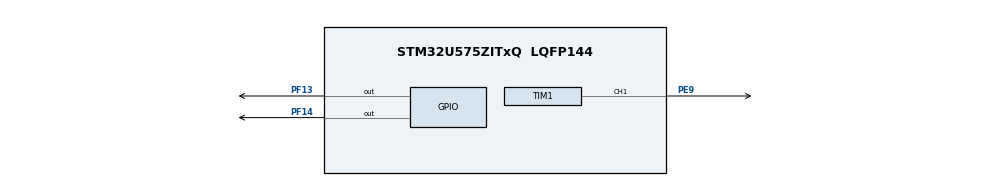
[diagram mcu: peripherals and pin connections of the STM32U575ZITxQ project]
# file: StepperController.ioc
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CORTEX_M33_NS.userName=CORTEX_M33
Mcu.Family=STM32U5
Mcu.Name=STM32U575ZITxQ
Mcu.Package=LQFP144
NUCLEO-U575ZI-Q.BUTTON=1
NUCLEO-U575ZI-Q.Bsp_Common_DEMO=true
NUCLEO-U575ZI-Q.LD1=true
NUCLEO-U575ZI-Q.LD2=true
NUCLEO-U575ZI-Q.LD3=true
NUCLEO-U575ZI-Q.VCP=true
NVIC.EXTI13_IRQn=true\:0\:0\:false\:false\:true\:false\:true\:true
NVIC.PriorityGroup=NVIC_PRIORITYGROUP_3
NVIC.TIM17_IRQn=true\:7\:0\:false\:false\:true\:false\:true\:true
NVIC.TIM1_UP_IRQn=true\:0\:0\:false\:false\:true\:true\:true\:true
NVIC.TimeBase=TIM17_IRQn
NVIC.TimeBaseIP=TIM17
PA10.Signal=USART1_RX
PA13\ (JTMS/SWDIO).Signal=DEBUG_JTMS-SWDIO
PA14\ (JTCK/SWCLK).Signal=DEBUG_JTCK-SWCLK
PA9.Signal=USART1_TX
PB3\ (JTDO/TRACESWO).Signal=DEBUG_JTDO-SWO
PC14-OSC32_IN\ (PC14).Signal=RCC_OSC32_IN
PC15-OSC32_OUT\ (PC15).Signal=RCC_OSC32_OUT
PE9.Signal=S_TIM1_CH1
PF13.Signal=GPIO_Output
PF14.Signal=GPIO_Output
PWR.PowerMode=PWR_SMPS_SUPPLY
ProjectManager.HeapSize=0x200
ProjectManager.StackSize=0x400
ProjectManager.TargetToolchain=CMake
RCC.ADCFreq_Value=16000000
RCC.DACCLockSelectionVirtual=RCC_DAC1CLKSOURCE_LSI
RCC.EPOD_VALUE=4000000
RCC.HSE_VALUE=16000000
RCC.HSI48_VALUE=48000000
RCC.HSI_VALUE=16000000
RCC.LSE_VALUE=32768
RCC.LSIDIV_VALUE=32000
RCC.MSI_VALUE=4000000
RCC.USBFreq_Value=48000000
RCC.VCOOutputFreq_Value=516000000
SH.S_TIM1_CH1.0=TIM1_CH1,PWM Generation1 CH1
TIM1.AutoReloadPreload=TIM_AUTORELOAD_PRELOAD_ENABLE
TIM1.Channel-PWM\ Generation1\ CH1=TIM_CHANNEL_1
TIM1.PeriodNoDither=999
TIM1.Prescaler=3
TIM1.PulseNoDither_1=10
VP_ICACHE_VS_ENABLE_ICACHE_MEMORY.Mode=Memoryregions
VP_ICACHE_VS_ICACHE.Mode=DirectMappedCache
VP_LPBAMQUEUE_VS_QUEUE.Mode=QUEUEMODE
VP_LPBAM_VS_SIG1.Mode=SmartRun
VP_LPBAM_VS_SIG4.Mode=LPDMA1
VP_MEMORYMAP_VS_MEMORYMAP.Mode=CurAppReg
VP_NUCLEO-U575ZI-Q_VS_BSP_COMMON.Mode=COMMON
VP_PWR_VS_DBSignals.Mode=DisableDeadBatterySignals
VP_PWR_VS_LPOM.Mode=PowerOptimisation
VP_PWR_VS_SECSignals.Mode=Security/Privilege
VP_SYS_VS_tim17.Mode=TIM17
VP_TIM1_VS_ClockSourceINT.Mode=Internal
board=NUCLEO-U575ZI-Q

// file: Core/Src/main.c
/* USER CODE BEGIN Header */
/**
  ******************************************************************************
  * @file           : main.c
  * @brief          : Main program body
  ******************************************************************************
  * @attention
  *
  * Copyright (c) 2026 STMicroelectronics.
  * All rights reserved.
  *
  * This software is licensed under terms that can be found in the LICENSE file
  * in the root directory of this software component.
  * If no LICENSE file comes with this software, it is provided AS-IS.
  *
  ******************************************************************************
  */
/* USER CODE END Header */
#include "main.h"

/* USER CODE BEGIN PD */
#define PERIOD 1000
#define SECOND (PERIOD*1000)
// button held at least this long = stop/start the motor
#define HOLD_TIME_MS 1000
// presses shorter than this are contact bounce and are ignored
#define DEBOUNCE_TIME_MS 30
/* USER CODE END PD */

COM_InitTypeDef BspCOMInit;
__IO uint32_t BspButtonState = BUTTON_RELEASED;

TIM_HandleTypeDef htim1;

void SystemClock_Config(void);
static void SystemPower_Config(void);
static void MX_GPIO_Init(void);
static void MX_ICACHE_Init(void);
static void MX_TIM1_Init(void);

/* USER CODE BEGIN 0 */
static uint32_t numOfPeriods = 0;
// button state, used only in the main loop
static uint8_t buttonHeld = 0;    // button is down, press not finished yet
static uint8_t holdHandled = 0;   // this press already stopped/started the motor
static uint32_t pressStart = 0;   // HAL_GetTick() when the button went down
static uint8_t motorRunning = 1;  // pulses are started at boot
/* USER CODE END 0 */

int main(void)
{

  /* MCU Configuration--------------------------------------------------------*/

  /* Reset of all peripherals, Initializes the Flash interface and the Systick. */
  HAL_Init();

  /* Configure the System Power */
  SystemPower_Config();

  /* Configure the system clock */
  SystemClock_Config();

  /* Initialize all configured peripherals */
  MX_GPIO_Init();
  MX_ICACHE_Init();
  MX_TIM1_Init();

  /* Initialize leds */
  BSP_LED_Init(LED_GREEN);
  BSP_LED_Init(LED_BLUE);
  BSP_LED_Init(LED_RED);

  /* Initialize USER push-button, will be used to trigger an interrupt each time it's pressed.*/
  BSP_PB_Init(BUTTON_USER, BUTTON_MODE_EXTI);

  /* Initialize COM1 port (115200, 8 bits (7-bit data + 1 stop bit), no parity */
  BspCOMInit.BaudRate   = 115200;
  BspCOMInit.WordLength = COM_WORDLENGTH_8B;
  BspCOMInit.StopBits   = COM_STOPBITS_1;
  BspCOMInit.Parity     = COM_PARITY_NONE;
  BspCOMInit.HwFlowCtl  = COM_HWCONTROL_NONE;
  if (BSP_COM_Init(COM1, &BspCOMInit) != BSP_ERROR_NONE)
  {
    Error_Handler();
  }

  /* USER CODE BEGIN BSP */

  /* -- Sample board code to send message over COM1 port ---- */
  printf("Welcome to STM32 world !\n\r");

  /* -- Sample board code to switch on leds ---- */
  BSP_LED_On(LED_GREEN);
  BSP_LED_On(LED_BLUE);
  BSP_LED_On(LED_RED);

  //!adam
  // Reset ENA (LOW is turned on)
  HAL_GPIO_WritePin(ENA_GPIO_PORT, ENA_PIN, GPIO_PIN_RESET);
  // Set DIR (unknown direction on SET)
  HAL_GPIO_WritePin(DIR_GPIO_PORT, DIR_PIN, GPIO_PIN_SET);
  HAL_Delay(1);
  // Start pulses
  __HAL_DBGMCU_FREEZE_TIM1();
  HAL_TIM_PWM_Start(&htim1, TIM_CHANNEL_1);
  HAL_TIM_Base_Start_IT(&htim1);
  /* USER CODE END BSP */

  /* Infinite loop */
  /* USER CODE BEGIN WHILE */
  while (1)
  {

    /* -- Sample board code for User push-button in interrupt mode ---- */
    if (BspButtonState == BUTTON_PRESSED)
    {
      /* Update button state */
      BspButtonState = BUTTON_RELEASED;
      // button went down - short press or hold is decided later
      if (!buttonHeld)
      {
        buttonHeld = 1;
        holdHandled = 0;
        pressStart = HAL_GetTick();
      }
    }

    if (buttonHeld)
    {
      uint32_t heldFor = HAL_GetTick() - pressStart;

      if (BSP_PB_GetState(BUTTON_USER) == GPIO_PIN_SET)
      {
        // still held: after HOLD_TIME_MS stop/start the motor (once per press)
        if (!holdHandled && heldFor >= HOLD_TIME_MS)
        {
          holdHandled = 1;
          if (motorRunning)
          {
            HAL_TIM_PWM_Stop(&htim1, TIM_CHANNEL_1);
            motorRunning = 0;
          }
          else
          {
            HAL_TIM_PWM_Start(&htim1, TIM_CHANNEL_1);
            motorRunning = 1;
          }
        }
      }
      else
      {
        // released: if it wasn't a hold (or a bounce), it was a short press
        buttonHeld = 0;
        if (!holdHandled && heldFor >= DEBOUNCE_TIME_MS)
        {
          /* -- Sample board code to toggle lecds ---- */
          BSP_LED_Toggle(LED_GREEN);
          BSP_LED_Toggle(LED_BLUE);
          BSP_LED_Toggle(LED_RED);

          /* ..... Perform your action ..... */
          if (motorRunning)
          {
            //stop pules
            HAL_TIM_PWM_Stop(&htim1, TIM_CHANNEL_1);
            // change direction
            HAL_GPIO_TogglePin(DIR_GPIO_PORT, DIR_PIN);
            HAL_Delay(1);
            //start again
            HAL_TIM_PWM_Start(&htim1, TIM_CHANNEL_1);
          }
          else
          {
            // stopped: only change direction, the next start uses it
            HAL_GPIO_TogglePin(DIR_GPIO_PORT, DIR_PIN);
          }
        }
      }
    }
    /* USER CODE END WHILE */

  }
}

void SystemClock_Config(void)
{
  RCC_OscInitTypeDef RCC_OscInitStruct = {0};
  RCC_ClkInitTypeDef RCC_ClkInitStruct = {0};

  /** Configure the main internal regulator output voltage
  */
  if (HAL_PWREx_ControlVoltageScaling(PWR_REGULATOR_VOLTAGE_SCALE4) != HAL_OK)
  {
    Error_Handler();
  }

  /** Initializes the CPU, AHB and APB buses clocks
  */
  RCC_OscInitStruct.OscillatorType = RCC_OSCILLATORTYPE_MSI;
  RCC_OscInitStruct.MSIState = RCC_MSI_ON;
  RCC_OscInitStruct.MSICalibrationValue = RCC_MSICALIBRATION_DEFAULT;
  RCC_OscInitStruct.MSIClockRange = RCC_MSIRANGE_4;
  RCC_OscInitStruct.PLL.PLLState = RCC_PLL_NONE;
  if (HAL_RCC_OscConfig(&RCC_OscInitStruct) != HAL_OK)
  {
    Error_Handler();
  }

  /** Initializes the CPU, AHB and APB buses clocks
  */
  RCC_ClkInitStruct.ClockType = RCC_CLOCKTYPE_HCLK|RCC_CLOCKTYPE_SYSCLK
                              |RCC_CLOCKTYPE_PCLK1|RCC_CLOCKTYPE_PCLK2
                              |RCC_CLOCKTYPE_PCLK3;
  RCC_ClkInitStruct.SYSCLKSource = RCC_SYSCLKSOURCE_MSI;
  RCC_ClkInitStruct.AHBCLKDivider = RCC_SYSCLK_DIV1;
  RCC_ClkInitStruct.APB1CLKDivider = RCC_HCLK_DIV1;
  RCC_ClkInitStruct.APB2CLKDivider = RCC_HCLK_DIV1;
  RCC_ClkInitStruct.APB3CLKDivider = RCC_HCLK_DIV1;

  if (HAL_RCC_ClockConfig(&RCC_ClkInitStruct, FLASH_LATENCY_0) != HAL_OK)
  {
    Error_Handler();
  }
}

/**
  * @brief Power Configuration
  * @retval None
  */
static void SystemPower_Config(void)
{

  /*
   * Disable the internal Pull-Up in Dead Battery pins of UCPD peripheral
   */
  HAL_PWREx_DisableUCPDDeadBattery();

  /*
   * Switch to SMPS regulator instead of LDO
   */
  if (HAL_PWREx_ConfigSupply(PWR_SMPS_SUPPLY) != HAL_OK)
  {
    Error_Handler();
  }
}

static void MX_ICACHE_Init(void)
{

  /** Enable instruction cache in 1-way (direct mapped cache)
  */
  if (HAL_ICACHE_ConfigAssociativityMode(ICACHE_1WAY) != HAL_OK)
  {
    Error_Handler();
  }
  if (HAL_ICACHE_Enable() != HAL_OK)
  {
    Error_Handler();
  }

}

static void MX_TIM1_Init(void)
{

  TIM_ClockConfigTypeDef sClockSourceConfig = {0};
  TIM_MasterConfigTypeDef sMasterConfig = {0};
  TIM_OC_InitTypeDef sConfigOC = {0};
  TIM_BreakDeadTimeConfigTypeDef sBreakDeadTimeConfig = {0};

  htim1.Instance = TIM1;
  htim1.Init.Prescaler = 3;
  htim1.Init.CounterMode = TIM_COUNTERMODE_UP;
  htim1.Init.Period = 999;
  htim1.Init.ClockDivision = TIM_CLOCKDIVISION_DIV1;
  htim1.Init.RepetitionCounter = 0;
  htim1.Init.AutoReloadPreload = TIM_AUTORELOAD_PRELOAD_ENABLE;
  if (HAL_TIM_Base_Init(&htim1) != HAL_OK)
  {
    Error_Handler();
  }
  sClockSourceConfig.ClockSource = TIM_CLOCKSOURCE_INTERNAL;
  if (HAL_TIM_ConfigClockSource(&htim1, &sClockSourceConfig) != HAL_OK)
  {
    Error_Handler();
  }
  if (HAL_TIM_PWM_Init(&htim1) != HAL_OK)
  {
    Error_Handler();
  }
  sMasterConfig.MasterOutputTrigger = TIM_TRGO_RESET;
  sMasterConfig.MasterOutputTrigger2 = TIM_TRGO2_RESET;
  sMasterConfig.MasterSlaveMode = TIM_MASTERSLAVEMODE_DISABLE;
  if (HAL_TIMEx_MasterConfigSynchronization(&htim1, &sMasterConfig) != HAL_OK)
  {
    Error_Handler();
  }
  sConfigOC.OCMode = TIM_OCMODE_PWM1;
  sConfigOC.Pulse = 10;
  sConfigOC.OCPolarity = TIM_OCPOLARITY_HIGH;
  sConfigOC.OCNPolarity = TIM_OCNPOLARITY_HIGH;
  sConfigOC.OCFastMode = TIM_OCFAST_DISABLE;
  sConfigOC.OCIdleState = TIM_OCIDLESTATE_RESET;
  sConfigOC.OCNIdleState = TIM_OCNIDLESTATE_RESET;
  if (HAL_TIM_PWM_ConfigChannel(&htim1, &sConfigOC, TIM_CHANNEL_1) != HAL_OK)
  {
    Error_Handler();
  }
  sBreakDeadTimeConfig.OffStateRunMode = TIM_OSSR_DISABLE;
  sBreakDeadTimeConfig.OffStateIDLEMode = TIM_OSSI_DISABLE;
  sBreakDeadTimeConfig.LockLevel = TIM_LOCKLEVEL_OFF;
  sBreakDeadTimeConfig.DeadTime = 0;
  sBreakDeadTimeConfig.BreakState = TIM_BREAK_DISABLE;
  sBreakDeadTimeConfig.BreakPolarity = TIM_BREAKPOLARITY_HIGH;
  sBreakDeadTimeConfig.BreakFilter = 0;
  sBreakDeadTimeConfig.BreakAFMode = TIM_BREAK_AFMODE_INPUT;
  sBreakDeadTimeConfig.Break2State = TIM_BREAK2_DISABLE;
  sBreakDeadTimeConfig.Break2Polarity = TIM_BREAK2POLARITY_HIGH;
  sBreakDeadTimeConfig.Break2Filter = 0;
  sBreakDeadTimeConfig.Break2AFMode = TIM_BREAK_AFMODE_INPUT;
  sBreakDeadTimeConfig.AutomaticOutput = TIM_AUTOMATICOUTPUT_DISABLE;
  if (HAL_TIMEx_ConfigBreakDeadTime(&htim1, &sBreakDeadTimeConfig) != HAL_OK)
  {
    Error_Handler();
  }
  HAL_TIM_MspPostInit(&htim1);

}

static void MX_GPIO_Init(void)
{
  GPIO_InitTypeDef GPIO_InitStruct = {0};

  /* GPIO Ports Clock Enable */
  __HAL_RCC_GPIOC_CLK_ENABLE();
  __HAL_RCC_GPIOF_CLK_ENABLE();
  __HAL_RCC_GPIOE_CLK_ENABLE();
  __HAL_RCC_GPIOA_CLK_ENABLE();
  __HAL_RCC_GPIOB_CLK_ENABLE();

  /*Configure GPIO pin Output Level */
  HAL_GPIO_WritePin(GPIOF, GPIO_PIN_13|GPIO_PIN_14, GPIO_PIN_RESET);

  /*Configure GPIO pins : PF13 PF14 */
  GPIO_InitStruct.Pin = GPIO_PIN_13|GPIO_PIN_14;
  GPIO_InitStruct.Mode = GPIO_MODE_OUTPUT_PP;
  GPIO_InitStruct.Pull = GPIO_NOPULL;
  GPIO_InitStruct.Speed = GPIO_SPEED_FREQ_LOW;
  HAL_GPIO_Init(GPIOF, &GPIO_InitStruct);

}

void HAL_TIM_PeriodElapsedCallback(TIM_HandleTypeDef *htim)
{
  if (htim->Instance == TIM17)
  {
    HAL_IncTick();
  }
}

/**
  * @brief BSP Push Button callback
  * @param Button Specifies the pressed button
  * @retval None
  */
void BSP_PB_Callback(Button_TypeDef Button)
{
  if (Button == BUTTON_USER)
  {
    BspButtonState = BUTTON_PRESSED;
  }
}

void Error_Handler(void)
{
  __disable_irq();
  while (1)
  {
  }
}
